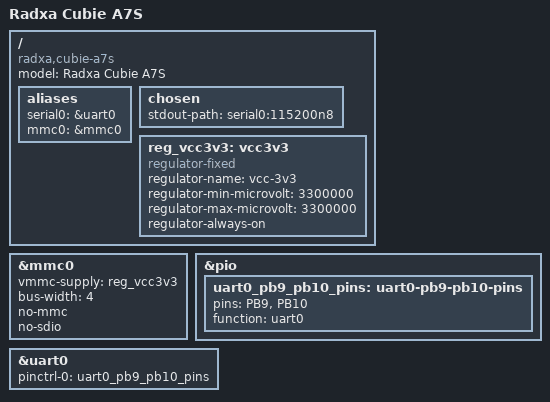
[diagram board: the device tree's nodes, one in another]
// SPDX-License-Identifier: (GPL-2.0-only OR MIT)

/dts-v1/;

#include "sun60i-a733.dtsi"

/ {
	model = "Radxa Cubie A7S";
	compatible = "radxa,cubie-a7s", "allwinner,sun60i-a733";

	aliases {
		serial0 = &uart0;
		mmc0 = &mmc0;
	};

	chosen {
		stdout-path = "serial0:115200n8";
	};

	reg_vcc3v3: vcc3v3 {
		compatible = "regulator-fixed";
		regulator-name = "vcc-3v3";
		regulator-min-microvolt = <3300000>;
		regulator-max-microvolt = <3300000>;
		regulator-always-on;
	};
};

&mmc0 {
	vmmc-supply = <&reg_vcc3v3>;
	bus-width = <4>;
	no-mmc;
	no-sdio;
	status = "okay";
};

&pio {
	uart0_pb9_pb10_pins: uart0-pb9-pb10-pins {
		pins = "PB9", "PB10";
		function = "uart0";
	};
};

&uart0 {
	pinctrl-names = "default";
	pinctrl-0 = <&uart0_pb9_pb10_pins>;
	status = "okay";
};
